# ATmega8515 device description
Architecture: AVR8; Family: megaAVR
Registers are 8-bit, access not given, no defined reset value unless marked. A register's access mark holds for its fields unless they carry their own. Offsets are from the block's base; [hi:lo] are bit positions.

## EXINT — External Interrupts
Instances: EXINT 0x00
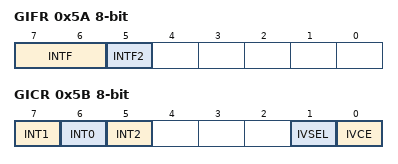
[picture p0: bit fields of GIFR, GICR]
0x5A GIFR — General Interrupt Flag Register
  [7:6] INTF — External Interrupt Flags
  [5] INTF2 — External Interrupt Flag 2
0x5B GICR — General Interrupt Control Register
  [7] INT1 — External Interrupt Request 1 Enable
  [6] INT0 — External Interrupt Request 0 Enable
  [5] INT2 — External Interrupt Request 2 Enable
  [1] IVSEL — Interrupt Vector Select
  [0] IVCE — Interrupt Vector Change Enable

## WDT — Watchdog Timer
Instances: WDT 0x00
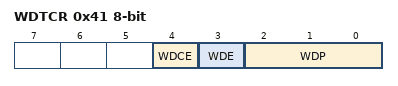
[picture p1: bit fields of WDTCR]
0x41 WDTCR — Watchdog Timer Control Register
  [4] WDCE — Watchdog Change Enable
  [3] WDE — Watch Dog Enable
  [2:0] WDP — Watch Dog Timer Prescaler bits
    0=Oscillator Cycles 16K; 1=Oscillator Cycles 32K; 2=Oscillator Cycles 64K; 3=Oscillator Cycles 128K; 4=Oscillator Cycles 256K; 5=Oscillator Cycles 512K; 6=Oscillator Cycles 1024K; 7=Oscillator Cycles 2048K

## TC0 (TC8 module) — Timer/Counter, 8-bit
Instances: TC0 0x00
0x51 OCR0 — Timer/Counter 0 Output Compare Register
0x52 TCNT0 — Timer/Counter 0 Register
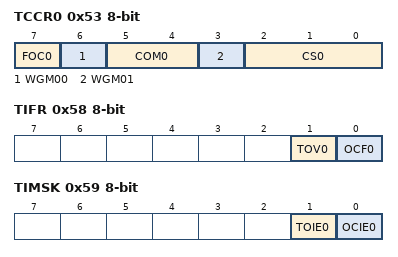
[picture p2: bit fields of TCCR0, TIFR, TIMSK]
0x53 TCCR0 — Timer/Counter 0 Control Register
  [7] FOC0 — Force Output Compare
  [6] WGM00 — Waveform Generation Mode 0
    0=Normal; 2=PWM, Phase Correct; 1=CTC; 3=Fast PWM
  [5:4] COM0 — Compare Match Output Modes
  [3] WGM01 — Waveform Generation Mode 1
  [2:0] CS0 — Clock Selects
    0=No Clock Source (Stopped); 1=Running, No Prescaling; 2=Running, CLK/8; 3=Running, CLK/64; 4=Running, CLK/256; 5=Running, CLK/1024; 6=Running, ExtClk Tx Falling Edge; 7=Running, ExtClk Tx Rising Edge
0x58 TIFR — Timer/Counter Interrupt Flag register
  [1] TOV0 — Timer/Counter0 Overflow Flag
  [0] OCF0 — Output Compare Flag 0
0x59 TIMSK — Timer/Counter Interrupt Mask Register
  [1] TOIE0 — Timer/Counter0 Overflow Interrupt Enable
  [0] OCIE0 — Timer/Counter0 Output Compare Match Interrupt register

## TC1 (TC16 module) — Timer/Counter, 16-bit
Instances: TC1 0x00
0x44 ICR1 16-bit — Timer/Counter1 Input Capture Register Bytes
0x48 OCR1B 16-bit — Timer/Counter1 Output Compare Register B Bytes
0x4A OCR1A 16-bit — Timer/Counter1 Output Compare Register A Bytes
0x4C TCNT1 16-bit — Timer/Counter1 Bytes
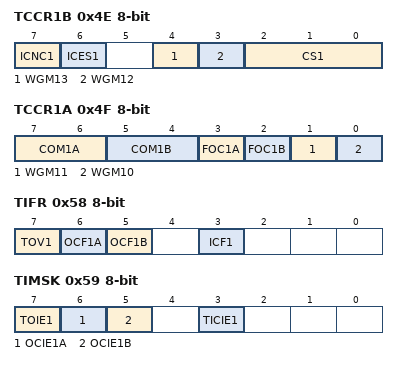
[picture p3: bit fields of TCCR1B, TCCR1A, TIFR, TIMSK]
0x4E TCCR1B — Timer/Counter1 Control Register B
  [7] ICNC1 — Input Capture 1 Noise Canceler
  [6] ICES1 — Input Capture 1 Edge Select
  [4] WGM13 (bit 2 of the value upward) — Waveform Generation Mode
  [3] WGM12 (bit 2 of the value upward) — Waveform Generation Mode
  [2:0] CS1 — Clock Select1 bits
    0=No Clock Source (Stopped); 1=Running, No Prescaling; 2=Running, CLK/8; 3=Running, CLK/64; 4=Running, CLK/256; 5=Running, CLK/1024; 6=Running, ExtClk Tx Falling Edge; 7=Running, ExtClk Tx Rising Edge
0x4F TCCR1A — Timer/Counter1 Control Register A
  [7:6] COM1A — Compare Output Mode 1A, bits
  [5:4] COM1B — Compare Output Mode 1B, bits
  [3] FOC1A — Force Output Compare for Channel A
  [2] FOC1B — Force Output Compare for Channel B
  [1] WGM11 — Waveform Generation Mode
  [0] WGM10 — Waveform Generation Mode
0x58 TIFR — Timer/Counter Interrupt Flag register
  [7] TOV1 — Timer/Counter1 Overflow Flag
  [6] OCF1A — Output Compare Flag 1A
  [5] OCF1B — Output Compare Flag 1B
  [3] ICF1 — Input Capture Flag 1
0x59 TIMSK — Timer/Counter Interrupt Mask Register
  [7] TOIE1 — Timer/Counter1 Overflow Interrupt Enable
  [6] OCIE1A — Timer/Counter1 Output CompareA Match Interrupt Enable
  [5] OCIE1B — Timer/Counter1 Output CompareB Match Interrupt Enable
  [3] TICIE1 — Timer/Counter1 Input Capture Interrupt Enable

## PORTA — I/O Port
Instances: PORTA 0x00
0x39 PINA — Port A Input Pins
0x3A DDRA — Port A Data Direction Register
0x3B PORTA — Port A Data Register

## PORTB — I/O Port
Instances: PORTB 0x00
0x36 PINB — Port B Input Pins
0x37 DDRB — Port B Data Direction Register
0x38 PORTB — Port B Data Register

## PORTC — I/O Port
Instances: PORTC 0x00
0x33 PINC — Port C Input Pins
0x34 DDRC — Port C Data Direction Register
0x35 PORTC — Port C Data Register

## PORTD — I/O Port
Instances: PORTD 0x00
0x30 PIND — Port D Input Pins
0x31 DDRD — Port D Data Direction Register
0x32 PORTD — Port D Data Register

## PORTE — I/O Port
Instances: PORTE 0x00
0x25 PINE bits used 2:0 — Port E Input Pins
0x26 DDRE bits used 2:0 — Port E Data Direction Register
0x27 PORTE bits used 2:0 — Port E Data Register

## EEPROM
Instances: EEPROM 0x00
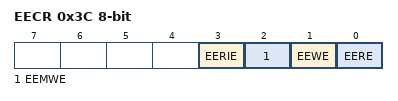
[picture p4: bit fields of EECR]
0x3C EECR — EEPROM Control Register
  [3] EERIE — EEPROM Ready Interrupt Enable
  [2] EEMWE — EEPROM Master Write Enable
  [1] EEWE — EEPROM Write Enable
  [0] EERE — EEPROM Read Enable
0x3D EEDR — EEPROM Data Register
0x3E EEAR 16-bit bits used 8:0 — EEPROM Address Register Bytes
